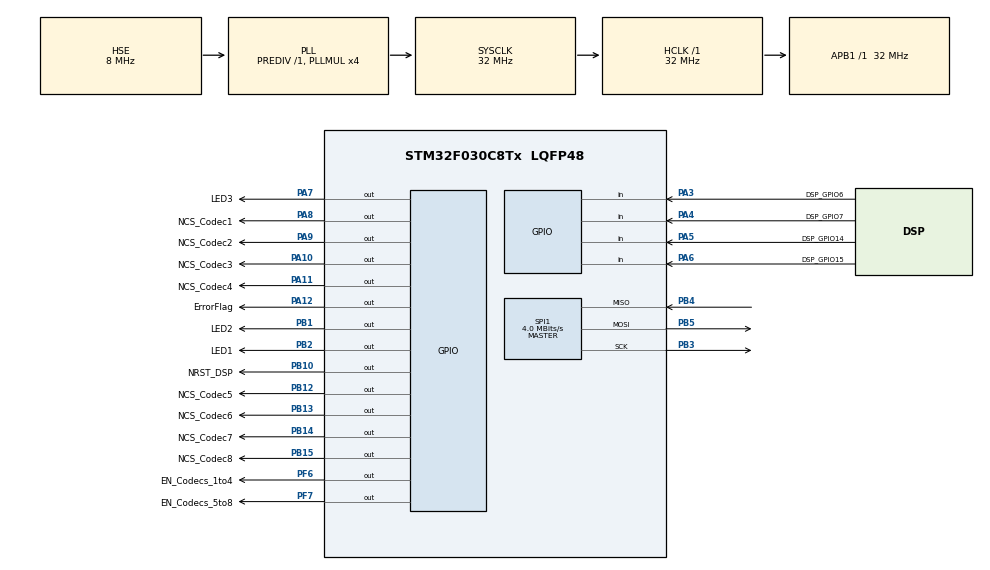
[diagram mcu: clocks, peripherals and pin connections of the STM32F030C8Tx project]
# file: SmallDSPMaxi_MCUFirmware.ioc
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Mcu.Family=STM32F0
Mcu.Name=STM32F030C8Tx
Mcu.Package=LQFP48
PA10.GPIO_Label=NCS_Codec3
PA10.GPIO_Speed=GPIO_SPEED_FREQ_HIGH
PA10.PinState=GPIO_PIN_SET
PA10.Signal=GPIO_Output
PA11.GPIO_Label=NCS_Codec4
PA11.GPIO_Speed=GPIO_SPEED_FREQ_HIGH
PA11.PinState=GPIO_PIN_SET
PA11.Signal=GPIO_Output
PA12.GPIO_Label=ErrorFlag
PA12.Signal=GPIO_Output
PA13.Mode=Serial_Wire
PA13.Signal=SYS_SWDIO
PA14.Mode=Serial_Wire
PA14.Signal=SYS_SWCLK
PA3.GPIO_Label=DSP_GPIO6
PA3.Signal=GPIO_Input
PA4.GPIO_Label=DSP_GPIO7
PA4.Signal=GPIO_Input
PA5.GPIO_Label=DSP_GPIO14
PA5.Signal=GPIO_Input
PA6.GPIO_Label=DSP_GPIO15
PA6.Signal=GPIO_Input
PA7.GPIO_Label=LED3
PA7.Signal=GPIO_Output
PA8.GPIO_Label=NCS_Codec1
PA8.GPIO_PuPd=GPIO_NOPULL
PA8.GPIO_Speed=GPIO_SPEED_FREQ_HIGH
PA8.PinState=GPIO_PIN_SET
PA8.Signal=GPIO_Output
PA9.GPIO_Label=NCS_Codec2
PA9.GPIO_Speed=GPIO_SPEED_FREQ_HIGH
PA9.PinState=GPIO_PIN_SET
PA9.Signal=GPIO_Output
PB1.GPIO_Label=LED2
PB1.Signal=GPIO_Output
PB10.GPIO_Label=NRST_DSP
PB10.PinState=GPIO_PIN_SET
PB10.Signal=GPIO_Output
PB12.GPIO_Label=NCS_Codec5
PB12.GPIO_Speed=GPIO_SPEED_FREQ_HIGH
PB12.PinState=GPIO_PIN_SET
PB12.Signal=GPIO_Output
PB13.GPIO_Label=NCS_Codec6
PB13.GPIO_Speed=GPIO_SPEED_FREQ_HIGH
PB13.PinState=GPIO_PIN_SET
PB13.Signal=GPIO_Output
PB14.GPIO_Label=NCS_Codec7
PB14.GPIO_Speed=GPIO_SPEED_FREQ_HIGH
PB14.PinState=GPIO_PIN_SET
PB14.Signal=GPIO_Output
PB15.GPIO_Label=NCS_Codec8
PB15.GPIO_Speed=GPIO_SPEED_FREQ_HIGH
PB15.PinState=GPIO_PIN_SET
PB15.Signal=GPIO_Output
PB2.GPIO_Label=LED1
PB2.Signal=GPIO_Output
PB3.Mode=Full_Duplex_Master
PB3.Signal=SPI1_SCK
PB4.Mode=Full_Duplex_Master
PB4.Signal=SPI1_MISO
PB5.Mode=Full_Duplex_Master
PB5.Signal=SPI1_MOSI
PF0-OSC_IN.Mode=HSE-External-Oscillator
PF0-OSC_IN.Signal=RCC_OSC_IN
PF1-OSC_OUT.Mode=HSE-External-Oscillator
PF1-OSC_OUT.Signal=RCC_OSC_OUT
PF6.GPIO_Label=EN_Codecs_1to4
PF6.Signal=GPIO_Output
PF7.GPIO_Label=EN_Codecs_5to8
PF7.Signal=GPIO_Output
ProjectManager.HeapSize=0x200
ProjectManager.StackSize=0x400
ProjectManager.TargetToolchain=STM32CubeIDE
RCC.AHBFreq_Value=32000000
RCC.APB1Freq_Value=32000000
RCC.APB1TimFreq_Value=32000000
RCC.HCLKFreq_Value=32000000
RCC.PLLMUL=RCC_PLL_MUL4
RCC.PLLSourceVirtual=RCC_PLLSOURCE_HSE
RCC.SYSCLKFreq_VALUE=32000000
RCC.SYSCLKSource=RCC_SYSCLKSOURCE_PLLCLK
SPI1.BaudRatePrescaler=SPI_BAUDRATEPRESCALER_8
SPI1.CLKPhase=SPI_PHASE_2EDGE
SPI1.CLKPolarity=SPI_POLARITY_HIGH
SPI1.CalculateBaudRate=4.0 MBits/s
SPI1.DataSize=SPI_DATASIZE_8BIT
SPI1.Direction=SPI_DIRECTION_2LINES
SPI1.Mode=SPI_MODE_MASTER
SPI1.VirtualType=VM_MASTER
board=custom

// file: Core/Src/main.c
/* USER CODE BEGIN Header */
/**
  ******************************************************************************
  * @file           : main.c
  * @brief          : Main program body
  ******************************************************************************
  * @attention
  *
  * Copyright (c) 2024 STMicroelectronics.
  * All rights reserved.
  *
  * This software is licensed under terms that can be found in the LICENSE file
  * in the root directory of this software component.
  * If no LICENSE file comes with this software, it is provided AS-IS.
  *
  ******************************************************************************
  */
/* USER CODE END Header */
#include "main.h"

SPI_HandleTypeDef hspi1;

void SystemClock_Config(void);
static void MX_GPIO_Init(void);
static void MX_SPI1_Init(void);

int main(void)
{
  /* USER CODE BEGIN 1 */
	uint8_t status = 0;
  /* USER CODE END 1 */

  /* MCU Configuration--------------------------------------------------------*/

  /* Reset of all peripherals, Initializes the Flash interface and the Systick. */
  HAL_Init();

  /* Configure the system clock */
  SystemClock_Config();

  /* Initialize all configured peripherals */
  MX_GPIO_Init();
  MX_SPI1_Init();
  /* USER CODE BEGIN 2 */
  HAL_GPIO_WritePin(ErrorFlag_GPIO_Port, ErrorFlag_Pin, GPIO_PIN_RESET);
  status = InitialiseCodecs();
  if(status)
	  HAL_GPIO_WritePin(ErrorFlag_GPIO_Port, ErrorFlag_Pin, GPIO_PIN_SET);
  /* USER CODE END 2 */

  /* Infinite loop */
  while (1)
  {

  }
}

void SystemClock_Config(void)
{
  RCC_OscInitTypeDef RCC_OscInitStruct = {0};
  RCC_ClkInitTypeDef RCC_ClkInitStruct = {0};

  /** Initializes the RCC Oscillators according to the specified parameters
  * in the RCC_OscInitTypeDef structure.
  */
  RCC_OscInitStruct.OscillatorType = RCC_OSCILLATORTYPE_HSE;
  RCC_OscInitStruct.HSEState = RCC_HSE_ON;
  RCC_OscInitStruct.PLL.PLLState = RCC_PLL_ON;
  RCC_OscInitStruct.PLL.PLLSource = RCC_PLLSOURCE_HSE;
  RCC_OscInitStruct.PLL.PLLMUL = RCC_PLL_MUL4;
  RCC_OscInitStruct.PLL.PREDIV = RCC_PREDIV_DIV1;
  if (HAL_RCC_OscConfig(&RCC_OscInitStruct) != HAL_OK)
  {
    Error_Handler();
  }

  /** Initializes the CPU, AHB and APB buses clocks
  */
  RCC_ClkInitStruct.ClockType = RCC_CLOCKTYPE_HCLK|RCC_CLOCKTYPE_SYSCLK
                              |RCC_CLOCKTYPE_PCLK1;
  RCC_ClkInitStruct.SYSCLKSource = RCC_SYSCLKSOURCE_PLLCLK;
  RCC_ClkInitStruct.AHBCLKDivider = RCC_SYSCLK_DIV1;
  RCC_ClkInitStruct.APB1CLKDivider = RCC_HCLK_DIV1;

  if (HAL_RCC_ClockConfig(&RCC_ClkInitStruct, FLASH_LATENCY_1) != HAL_OK)
  {
    Error_Handler();
  }
}

static void MX_SPI1_Init(void)
{

  /* SPI1 parameter configuration*/
  hspi1.Instance = SPI1;
  hspi1.Init.Mode = SPI_MODE_MASTER;
  hspi1.Init.Direction = SPI_DIRECTION_2LINES;
  hspi1.Init.DataSize = SPI_DATASIZE_8BIT;
  hspi1.Init.CLKPolarity = SPI_POLARITY_HIGH;
  hspi1.Init.CLKPhase = SPI_PHASE_2EDGE;
  hspi1.Init.NSS = SPI_NSS_SOFT;
  hspi1.Init.BaudRatePrescaler = SPI_BAUDRATEPRESCALER_8;
  hspi1.Init.FirstBit = SPI_FIRSTBIT_MSB;
  hspi1.Init.TIMode = SPI_TIMODE_DISABLE;
  hspi1.Init.CRCCalculation = SPI_CRCCALCULATION_DISABLE;
  hspi1.Init.CRCPolynomial = 7;
  hspi1.Init.CRCLength = SPI_CRC_LENGTH_DATASIZE;
  hspi1.Init.NSSPMode = SPI_NSS_PULSE_DISABLE;
  if (HAL_SPI_Init(&hspi1) != HAL_OK)
  {
    Error_Handler();
  }

}

static void MX_GPIO_Init(void)
{
  GPIO_InitTypeDef GPIO_InitStruct = {0};

  /* GPIO Ports Clock Enable */
  __HAL_RCC_GPIOF_CLK_ENABLE();
  __HAL_RCC_GPIOA_CLK_ENABLE();
  __HAL_RCC_GPIOB_CLK_ENABLE();

  /*Configure GPIO pin Output Level */
  HAL_GPIO_WritePin(GPIOA, LED3_Pin|ErrorFlag_Pin, GPIO_PIN_RESET);

  /*Configure GPIO pin Output Level */
  HAL_GPIO_WritePin(GPIOB, LED2_Pin|LED1_Pin, GPIO_PIN_RESET);

  /*Configure GPIO pin Output Level */
  HAL_GPIO_WritePin(GPIOB, NRST_DSP_Pin|NCS_Codec5_Pin|NCS_Codec6_Pin|NCS_Codec7_Pin
                          |NCS_Codec8_Pin, GPIO_PIN_SET);

  /*Configure GPIO pin Output Level */
  HAL_GPIO_WritePin(GPIOA, NCS_Codec1_Pin|NCS_Codec2_Pin|NCS_Codec3_Pin|NCS_Codec4_Pin, GPIO_PIN_SET);

  /*Configure GPIO pin Output Level */
  HAL_GPIO_WritePin(GPIOF, EN_Codecs_1to4_Pin|EN_Codecs_5to8_Pin, GPIO_PIN_RESET);

  /*Configure GPIO pins : DSP_GPIO6_Pin DSP_GPIO7_Pin DSP_GPIO14_Pin DSP_GPIO15_Pin */
  GPIO_InitStruct.Pin = DSP_GPIO6_Pin|DSP_GPIO7_Pin|DSP_GPIO14_Pin|DSP_GPIO15_Pin;
  GPIO_InitStruct.Mode = GPIO_MODE_INPUT;
  GPIO_InitStruct.Pull = GPIO_NOPULL;
  HAL_GPIO_Init(GPIOA, &GPIO_InitStruct);

  /*Configure GPIO pins : LED3_Pin ErrorFlag_Pin */
  GPIO_InitStruct.Pin = LED3_Pin|ErrorFlag_Pin;
  GPIO_InitStruct.Mode = GPIO_MODE_OUTPUT_PP;
  GPIO_InitStruct.Pull = GPIO_NOPULL;
  GPIO_InitStruct.Speed = GPIO_SPEED_FREQ_LOW;
  HAL_GPIO_Init(GPIOA, &GPIO_InitStruct);

  /*Configure GPIO pins : LED2_Pin LED1_Pin NRST_DSP_Pin */
  GPIO_InitStruct.Pin = LED2_Pin|LED1_Pin|NRST_DSP_Pin;
  GPIO_InitStruct.Mode = GPIO_MODE_OUTPUT_PP;
  GPIO_InitStruct.Pull = GPIO_NOPULL;
  GPIO_InitStruct.Speed = GPIO_SPEED_FREQ_LOW;
  HAL_GPIO_Init(GPIOB, &GPIO_InitStruct);

  /*Configure GPIO pins : NCS_Codec5_Pin NCS_Codec6_Pin NCS_Codec7_Pin NCS_Codec8_Pin */
  GPIO_InitStruct.Pin = NCS_Codec5_Pin|NCS_Codec6_Pin|NCS_Codec7_Pin|NCS_Codec8_Pin;
  GPIO_InitStruct.Mode = GPIO_MODE_OUTPUT_PP;
  GPIO_InitStruct.Pull = GPIO_NOPULL;
  GPIO_InitStruct.Speed = GPIO_SPEED_FREQ_HIGH;
  HAL_GPIO_Init(GPIOB, &GPIO_InitStruct);

  /*Configure GPIO pins : NCS_Codec1_Pin NCS_Codec2_Pin NCS_Codec3_Pin NCS_Codec4_Pin */
  GPIO_InitStruct.Pin = NCS_Codec1_Pin|NCS_Codec2_Pin|NCS_Codec3_Pin|NCS_Codec4_Pin;
  GPIO_InitStruct.Mode = GPIO_MODE_OUTPUT_PP;
  GPIO_InitStruct.Pull = GPIO_NOPULL;
  GPIO_InitStruct.Speed = GPIO_SPEED_FREQ_HIGH;
  HAL_GPIO_Init(GPIOA, &GPIO_InitStruct);

  /*Configure GPIO pins : EN_Codecs_1to4_Pin EN_Codecs_5to8_Pin */
  GPIO_InitStruct.Pin = EN_Codecs_1to4_Pin|EN_Codecs_5to8_Pin;
  GPIO_InitStruct.Mode = GPIO_MODE_OUTPUT_PP;
  GPIO_InitStruct.Pull = GPIO_NOPULL;
  GPIO_InitStruct.Speed = GPIO_SPEED_FREQ_LOW;
  HAL_GPIO_Init(GPIOF, &GPIO_InitStruct);

}

void Error_Handler(void)
{
  __disable_irq();
  while (1)
  {
  }
}
